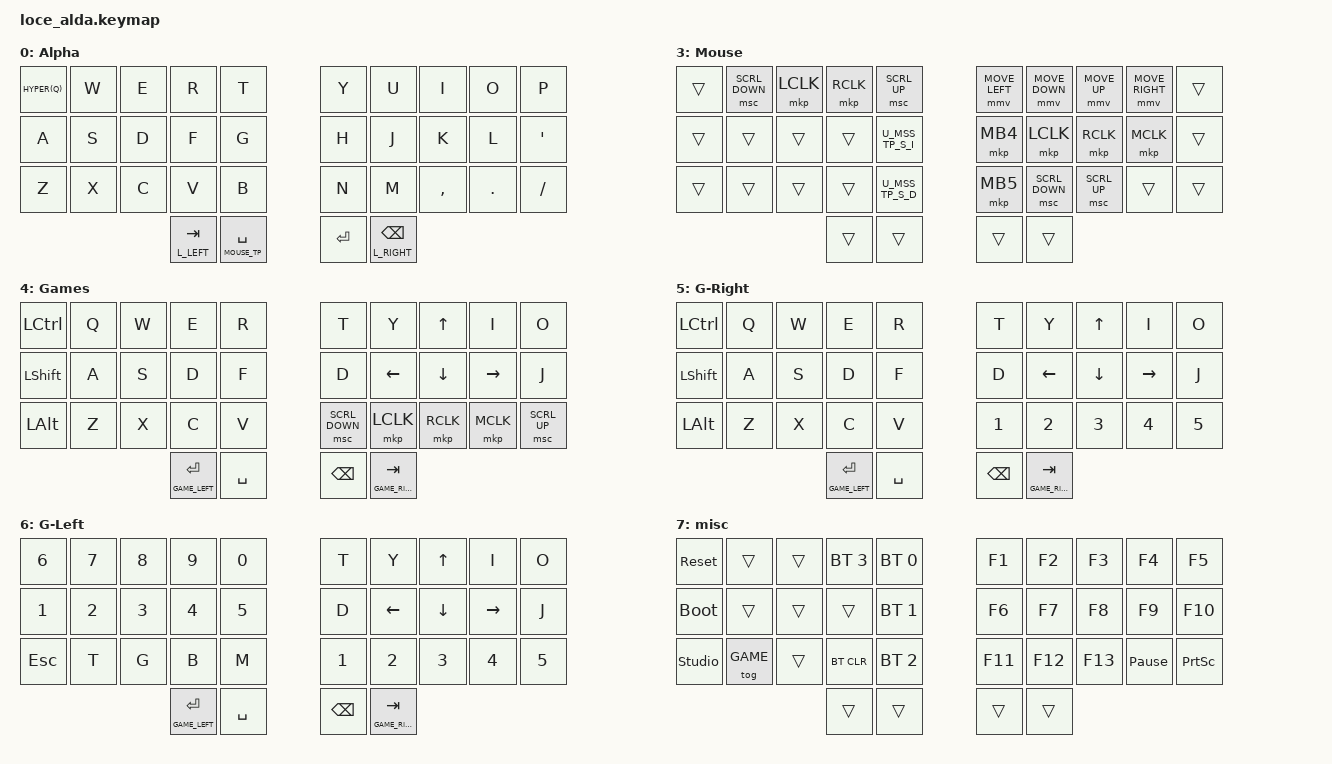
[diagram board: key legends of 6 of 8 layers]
#include <behaviors.dtsi>
#include <dt-bindings/zmk/keys.h>

#include <dt-bindings/zmk/bt.h>
#include <dt-bindings/zmk/ext_power.h>
#include <dt-bindings/zmk/outputs.h>

#include <input/processors.dtsi>
#include <dt-bindings/zmk/input_transform.h>
#include <zephyr/dt-bindings/input/input-event-codes.h>
#include <dt-bindings/zmk/mouse.h>
#include <behaviors/mouse_keys.dtsi>
#include "include/mouse_tp.dtsi"
#include "include/globals.h"


// Home row mods macro
#define HRML(k1,k2,k3,k4) &ht LSHFT k1  &ht LALT k2  &ht LCTRL k3  &ht LGUI k4
#define HRMR(k1,k2,k3,k4) &ht RGUI k1  &ht RCTRL k2  &ht RALT k3  &ht RSHFT k4
#define HYPER(k1) &ht LS(LC(LA(LGUI))) k1

/ {

    behaviors {
        ht: hold_tap {
            compatible = "zmk,behavior-hold-tap";
            #binding-cells = <2>;
            flavor = "balanced";
            tapping-term-ms = <200>;
            quick-tap-ms = <180>;
            bindings = <&kp>, <&kp>;
        };
    };

    conditional_layers {
        compatible = "zmk,conditional-layers";
        misc_layer {
            if-layers = <L_RIGHT L_LEFT>;
            then-layer = <MISC>;    
        };

        misc_layer_Game {
            if-layers = <GAME_RIGHT GAME_LEFT>;
            then-layer = <MISC>;
        };

    };

    keymap {
        compatible = "zmk,keymap";
        Base_layer {
            display-name = "Alpha";
            bindings = <
            //╭──────────┬──────────┬──────────┬──────────┬──────────╮   ╭──────────┬──────────┬──────────┬──────────┬──────────╮
            //│  Q       │  W       │  E       │  R       │  T       │   │  Y       │  U       │  I       │  O       │  P       │
                HYPER(Q)      &kp W      &kp E      &kp R      &kp T          &kp Y      &kp U      &kp I      &kp O   &kp P
            //├──────────┼──────────┼──────────┼──────────┼──────────┤   ├──────────┼──────────┼──────────┼──────────┼──────────┤
            //│  A       │  S       │  D       │  F       │  G       │   │  H       │  J       │  K       │  L       │ ' "      │
                &kp A       &kp S        &kp D        &kp F     &kp G          &kp H     &kp J      &kp  K       &kp  L      &kp  SQT
            //├──────────┼──────────┼──────────┼──────────┼──────────┤   ├──────────┼──────────┼──────────┼──────────┼──────────┤
            //│  Z       │  X       │  C       │  V       │  B       │   │  N       │  M       │ , <│ .>      │ / ?      │
                &kp Z      &kp X      &kp C      &kp V      &kp B          &kp N      &kp M      &kp COMMA  &kp DOT    &kp FSLH
            //╰──────────┴──────────┴──────────┼──────────┼──────────┤   ├──────────┼──────────┼──────────┴──────────┴──────────╯
                                    &lt L_LEFT TAB  &lt MOUSE_TP SPACE    &kp ENTER  &lt L_RIGHT BSPC
            //                     ╰──────────────┴──────────────────╯   ╰──────────┴────────────────╯
            >;
        };

        right_layer {
            display-name = "Nav";
            bindings = <
            //╭──────────┬──────────┬──────────┬──────────┬──────────╮   ╭──────────┬──────────┬──────────┬──────────┬──────────╮
            //│ HOME     │ UP       │  END     │ PAGE UP  │ DEL      │   │ HOME     │ PAGE DN  │ PAGE UP  │ END      │  :       │
                &kp HOME   &kp UP     &kp END   &kp PG_UP  &kp DEL          &kp HOME   &kp PG_DN  &kp PG_UP  &kp END    &kp COLON
            //├──────────┼──────────┼──────────┼──────────┼──────────┤   ├──────────┼──────────┼──────────┼──────────┼──────────┤
            //│ LEFT     │  DOWN    │ RIGHT    │ PAGE DOWN│ ESC      │   │ LEFT     │ DOWN     │ UP       │ RIGHT    │  ;       │
                &kp LEFT   &kp DOWN   &kp RIGHT  &kp PG_DN  &kp ESC         &kp LARW   HRMR(DARW,  UARW,    RARW,      SEMI)
            //├──────────┼──────────┼──────────┼──────────┼──────────┤   ├──────────┼──────────┼──────────┼──────────┼──────────┤
            //│ CAPS     │ PRINT SC │volume up │volume dwn│  Next    │   │ PREV SONG│    -     │     +    │   `      │   ~      │
                &caps_word  &trans   &trans      &trans     &trans         &trans      &kp MINUS  &kp PLUS   &kp GRAVE  &kp TILDE
            //╰──────────┴──────────┴──────────┼──────────┼──────────┤   ├──────────┼──────────┼──────────┴──────────┴──────────╯
                                                &trans      &trans        &trans     &trans
            //                                 ╰──────────┴──────────╯   ╰──────────┴──────────╯
            >;
        };

        left_layer {
            display-name = "Num";
            bindings = <
            //╭──────────┬──────────┬──────────┬──────────┬──────────╮   ╭──────────┬──────────┬──────────┬──────────┬──────────╮
            //│    !     │  @       │  #       │  $       │ %        │   │  ^       │  &       │  *       │  (       │  )       │
                &kp EXCL   &kp AT     &kp HASH   &kp DLLR   &kp PRCNT      &kp CARET   &kp AMPS   &kp ASTRK  &kp LPAR  &kp RPAR
            //├──────────┼──────────┼──────────┼──────────┼──────────┤   ├──────────┼──────────┼──────────┼──────────┼──────────┤
            //│   1      │  2       │  3       │  4       │  5       │   │  6       │  7       │  8       │  9       │  0       │
                HRML(N1,    N2,       N3,        N4)        &kp N5         &kp N6     HRMR(N7,   N8,        N9,         N0)
            //├──────────┼──────────┼──────────┼──────────┼──────────┤   ├──────────┼──────────┼──────────┼──────────┼──────────┤
            //│  esc     │          │  _       │    =     │  del     │   │  [       │   ]      │  <│>       │         │
                &kp ESC     &kp BSLH  &kp UNDER &kp EQUAL   &kp DEL       &kp LBKT    &kp RBKT   &kp LT     &kp GT     &kp PIPE
            //╰──────────┴──────────┴──────────┼──────────┼──────────┤   ├──────────┼──────────┼──────────┴──────────┴──────────╯
                                            &trans &lt MOUSE_TP SPACE      &trans     &trans
            //                                 ╰──────────┴──────────╯   ╰──────────┴──────────╯
            >;
        };

        Mouse_trackpoint_layer {
            display-name = "Mouse";
            bindings = <
            //╭─────────────┬─────────────┬─────────────┬─────────────┬─────────────╮   ╭─────────────┬─────────────┬─────────────┬─────────────┬─────────────╮
            //│             │             │             │             │             │   │             │             │             │             │             │
            &trans        &msc SCRL_DOWN       &mkp LCLK    &mkp RCLK      &msc SCRL_UP        &mmv MOVE_LEFT &mmv MOVE_DOWN &mmv MOVE_UP &mmv MOVE_RIGHT  &trans
            //├─────────────┼─────────────┼─────────────┼─────────────┼─────────────┤   ├─────────────┼─────────────┼─────────────┼─────────────┼─────────────┤
            //│             │             │             │             │             │   │   MB4       │  LFT_CLK    │ RGHT_CLK    │ MDL_CLK     │             │
            &trans        &trans        &trans        &trans        U_MSS_TP_S_I       &mkp MB4     &mkp LCLK     &mkp RCLK     &mkp MCLK      &trans
            //├─────────────┼─────────────┼─────────────┼─────────────┼─────────────┤   ├─────────────┼─────────────┼─────────────┼─────────────┼─────────────┤
            //│             │             │             │             │             │   │     MB5     │    SCR_DWN   │    SCR_UP  │             │             │
            &trans        &trans      &trans         &trans      U_MSS_TP_S_D        &mkp MB5     &msc SCRL_DOWN &msc SCRL_UP   &trans       &trans
            //╰─────────────┴─────────────┴─────────────┼─────────────┼─────────────┤   ├─────────────┼─────────────┼─────────────┴─────────────┴─────────────╯
            &trans     &trans              &trans     &trans
            //                                          ╰─────────────┴─────────────╯   ╰─────────────┴─────────────╯
            >;
        };

        Game_layer {
            display-name = "Games";
            bindings = <
            //╭──────────┬──────────┬──────────┬──────────┬──────────╮   ╭──────────┬──────────┬──────────┬──────────┬──────────╮
            //│  CTRL    │  Q       │  W       │  E       │  R       │   │  T       │  Y       │  UP      │  I       │  O       │
                &kp LCTRL   &kp Q      &kp W      &kp E      &kp R          &kp T      &kp Y      &kp UP      &kp I      &kp O
            //├──────────┼──────────┼──────────┼──────────┼──────────┤   ├──────────┼──────────┼──────────┼──────────┼──────────┤
            //│  SHIFT   │  A       │ S        │  D       │  F       │   │  D       │  LEFT    │  DOWN    │  RIGHT   │  J       │
                &kp LSHFT   &kp A     &kp S       &kp D      &kp F          &kp D      &kp LEFT   &kp DOWN   &kp RIGHT  &kp J
            //├──────────┼──────────┼──────────┼──────────┼──────────┤   ├──────────┼──────────┼──────────┼──────────┼──────────┤
            //│  Alt     │  Z       │  X       │  C       │  V       │   │ 1        │ 2        │ 3        │ 4        │ 5        │
                &kp LALT  &kp Z      &kp X      &kp C      &kp V       &msc SCRL_DOWN &mkp LCLK   &mkp RCLK  &mkp MCLK  &msc SCRL_UP 
            //╰──────────┴──────────┴──────────┼──────────┼──────────╯   ╰──────────┼──────────┴──────────┴──────────┴──────────╯
            &lt GAME_LEFT ENTER    &kp SPACE      &kp BSPC   &lt GAME_RIGHT TAB
            //                     ╰──────────────┴──────────────────╯   ╰──────────┴────────────────╯
            >;
        };

        game_right_layer {
            display-name = "G-Right";
            bindings = <
            //╭──────────┬──────────┬──────────┬──────────┬──────────╮   ╭──────────┬──────────┬──────────┬──────────┬──────────╮
            //│  CTRL    │  Q       │  W       │  E       │  R       │   │  T       │  Y       │  UP      │  I       │  O       │
            &kp LCTRL   &kp Q      &kp W      &kp E      &kp R          &kp T      &kp Y      &kp UP      &kp I      &kp O
            //├──────────┼──────────┼──────────┼──────────┼──────────┤   ├──────────┼──────────┼──────────┼──────────┼──────────┤
            //│  SHIFT   │  A       │ S        │  D       │  F       │   │  D       │  LEFT    │  DOWN    │  RIGHT   │  J       │
            &kp LSHFT   &kp A     &kp S       &kp D      &kp F          &kp D      &kp LEFT   &kp DOWN   &kp RIGHT  &kp J
            //├──────────┼──────────┼──────────┼──────────┼──────────┤   ├──────────┼──────────┼──────────┼──────────┼──────────┤
            //│  Alt     │  Z       │  X       │  C       │  V       │   │ 1        │ 2        │ 3        │ 4        │ 5        │
            &kp LALT  &kp Z      &kp X      &kp C      &kp V           &kp N1     &kp N2     &kp N3     &kp N4     &kp N5
            //╰──────────┴──────────┴──────────┼──────────┼──────────╯   ╰──────────┼──────────┴──────────┴──────────┴──────────╯
            &lt GAME_LEFT ENTER    &kp SPACE      &kp BSPC   &lt GAME_RIGHT TAB
            //                     ╰──────────────┴──────────────────╯   ╰──────────┴────────────────╯
            >;
        };

        game_left_layer {
            display-name = "G-Left";
            bindings = <
            //╭──────────┬──────────┬──────────┬──────────┬──────────╮   ╭──────────┬──────────┬──────────┬──────────┬──────────╮
            //│    6     │  7       │  8       │  9       │ 0        │   │  T       │  Y       │  UP      │  I       │  O       │
            &kp N6    &kp N7     &kp  N8   &kp N9     &kp N0         &kp T      &kp Y      &kp UP      &kp I      &kp O
            //├──────────┼──────────┼──────────┼──────────┼──────────┤   ├──────────┼──────────┼──────────┼──────────┼──────────┤
            //│   1      │  2       │  3       │  4       │  5       │   │  D       │  LEFT    │  DOWN    │  RIGHT   │  J       │
            &kp N1    &kp N2     &kp  N3   &kp N4     &kp N5          &kp D      &kp LEFT   &kp DOWN   &kp RIGHT  &kp J
            //├──────────┼──────────┼──────────┼──────────┼──────────┤   ├──────────┼──────────┼──────────┼──────────┼──────────┤
            //│  esc     │  T       │ G     │    B        │ M        │   │ 1        │ 2        │ 3        │ 4        │ 5        │
            &kp ESC      &kp T     &kp G      &kp B      &kp M          &kp N1     &kp N2     &kp N3     &kp N4     &kp N5
            //╰──────────┴──────────┴──────────┼──────────┼──────────┤   ╰──────────┼──────────┴──────────┴──────────┴──────────╯
            &lt GAME_LEFT ENTER    &kp SPACE   &kp BSPC   &lt GAME_RIGHT TAB
            //                                 ╰──────────┴──────────╯   ╰──────────┴──────────╯
            >;
        };

        misc_layer {
            display-name = "misc";
            bindings = <
            //╭──────────┬──────────┬──────────┬──────────┬──────────╮   ╭──────────┬──────────┬──────────┬──────────┬──────────╮
            //│ RESET    │          │          │ PROFILE  │PROFILE 0 │   │   F1     │   F2     │   F3     │   F4     │   F5     │
            &sys_reset  &trans     &trans  &bt BT_SEL 3 &bt BT_SEL 0   &kp F1    &kp F2     &kp F3     &kp F4    &kp F5
            //├──────────┼──────────┼──────────┼──────────┼──────────┤   ├──────────┼──────────┼──────────┼──────────┼──────────┤
            //│BOOTLOADER│          │          │          │PROFILE 1 │   │   F6     │   F7     │   F8     │   F9     │   F10    │
            &bootloader  &trans     &trans     &trans    &bt BT_SEL 1    &kp F6    &kp F7     &kp F8     &kp F9    &kp F10
            //├──────────┼──────────┼──────────┼──────────┼──────────┤   ├──────────┼──────────┼──────────┼──────────┼──────────┤
            //│          │          │          │ CLEAR BT │PROFILE 2 │   │   F11    │   F12    │   F13       │   PAUSE  │  PRINT   │
            &studio_unlock &tog GAME &trans &bt BT_CLR &bt BT_SEL 2    &kp F11   &kp F12    &kp F13  &kp PAUSE_BREAK &kp PSCRN
            //╰──────────┴──────────┴──────────┼──────────┼──────────┤   ├──────────┼──────────┼──────────┴──────────┴──────────╯
            &trans     &trans         &trans     &trans
            //                                 ╰──────────┴──────────╯   ╰──────────┴──────────╯
            >;
        };

        extra1 {
            status = "reserved";
        };

        extra2 {
            status = "reserved";
        };

    };
};
